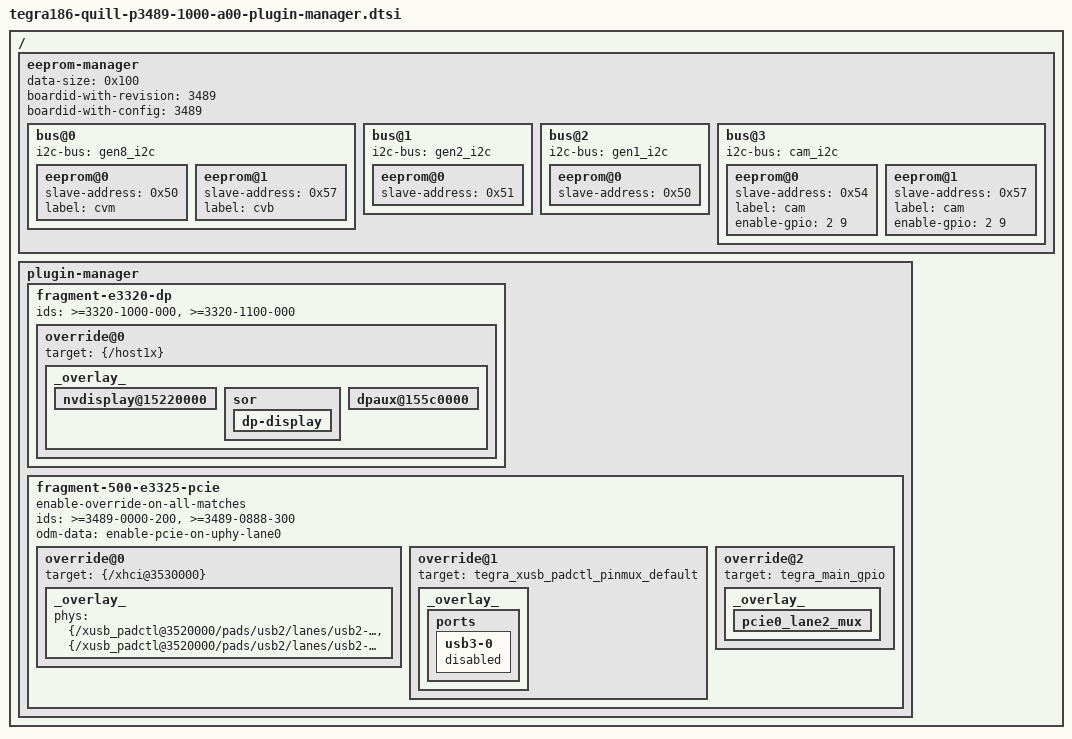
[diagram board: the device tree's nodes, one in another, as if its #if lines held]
/*
 * tegra186-quill-p3489-0000-a00-plugin-manager.dtsi: P3489 plugin manager
 *
 * Copyright (c) 2015-2019, NVIDIA CORPORATION.  All rights reserved.
 *
 * This program is free software; you can redistribute it and/or modify
 * it under the terms of the GNU General Public License as published by
 * the Free Software Foundation; version 2 of the License.
 *
 * This program is distributed in the hope that it will be useful, but WITHOUT
 * ANY WARRANTY; without even the implied warranty of MERCHANTABILITY or
 * FITNESS FOR A PARTICULAR PURPOSE.  See the GNU General Public License for
 * more details.
 */

#include "tegra186-soc-prod-plugin-manager.dtsi"
#include "tegra186-odm-data-plugin-manager.dtsi"

/ {
	eeprom-manager {
		data-size = <0x100>;
		boardid-with-revision = <3489>;
		boardid-with-config = <3489>;
		bus@0 {
			i2c-bus = <&gen8_i2c>;
			eeprom@0 {
				slave-address = <0x50>;
				label = "cvm";
			};
			eeprom@1 {
				slave-address = <0x57>;
				label = "cvb";
			};
		};
		bus@1 {
			i2c-bus = <&gen2_i2c>;
			eeprom@0 {
				slave-address = <0x51>;
			};
		};
		bus@2 {
			i2c-bus = <&gen1_i2c>;
			eeprom@0 {
				slave-address = <0x50>;
			};
		};
		bus@3 {
			i2c-bus = <&cam_i2c>;
			eeprom@0 {
				slave-address = <0x54>;
				label = "cam";
				enable-gpio = <2 9>;
			};
			eeprom@1 {
				slave-address = <0x57>;
				label = "cam";
				enable-gpio = <2 9>;
			};
		};
	};
	plugin-manager {
		fragment-e3320-dp {
			ids = ">=3320-1000-000", ">=3320-1100-000";
			override@0 {
				target = <&{/host1x}>;
				_overlay_ {
					nvdisplay@15220000 {
						status = "okay";
					};
					sor {
						status = "okay";
						dp-display {
							status = "okay";
						};
					};
					dpaux@155c0000 {
						status = "okay";
					};
				};
			};
		};

		fragment-500-e3325-pcie {
			enable-override-on-all-matches;
			ids = ">=3489-0000-200", ">=3489-0888-300";
			odm-data = "enable-pcie-on-uphy-lane0";
			override@0 {
				target = <&{/xhci@3530000}>;
#if TEGRA_XUSB_PADCONTROL_VERSION >= DT_VERSION_2
				_overlay_ {
					phys = <&{/xusb_padctl@3520000/pads/usb2/lanes/usb2-0}>,
						<&{/xusb_padctl@3520000/pads/usb2/lanes/usb2-1}>;
					phy-names = "usb2-0", "usb2-1";
				};
#else
				_overlay_ {
					phys = <&tegra_xusb_padctl TEGRA_PADCTL_PHY_UTMI_P(0)>,
						<&tegra_xusb_padctl TEGRA_PADCTL_PHY_UTMI_P(1)>;
					phy-names = "utmi-0", "utmi-1";
				};
#endif
			};
			override@1 {
				target = <&tegra_xusb_padctl_pinmux_default>;
#if TEGRA_XUSB_PADCONTROL_VERSION >= DT_VERSION_2
				_overlay_ {
					ports {
						usb3-0 {
							status = "disabled";
						};
					};
				};
#else
				_overlay_ {
					usb3-std-A-port2 {
						status = "disabled";
					};
				};
#endif
			};

			override@2 {
				target = <&tegra_main_gpio>;
				_overlay_ {
					pcie0_lane2_mux {
						status = "okay";
					};
				};
			};
		};
	};
};
